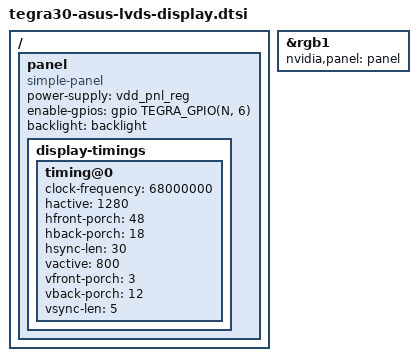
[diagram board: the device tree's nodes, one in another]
// SPDX-License-Identifier: GPL-2.0

/* This dtsi file describes parts common for Asus T30 devices with a LVDS panel. */

#include "tegra30.dtsi"

/ {
	panel: panel {
		compatible = "simple-panel";

		power-supply = <&vdd_pnl_reg>;
		enable-gpios = <&gpio TEGRA_GPIO(N, 6) GPIO_ACTIVE_HIGH>;

		backlight = <&backlight>;

		display-timings {
			timing@0 {
				/* 1280x800@60Hz */
				clock-frequency = <68000000>;

				hactive = <1280>;
				hfront-porch = <48>;
				hback-porch = <18>;
				hsync-len = <30>;

				vactive = <800>;
				vfront-porch = <3>;
				vback-porch = <12>;
				vsync-len = <5>;
			};
		};
	};
};

&rgb1 {
	status = "okay";

	nvidia,panel = <&panel>;
};
